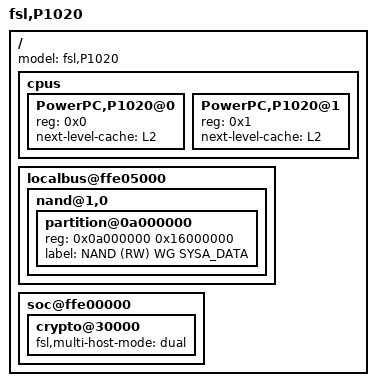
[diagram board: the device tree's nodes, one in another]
/*
 * P1020 RDB Device Tree Source
 *
 * Copyright 2010 Freescale Semiconductor Inc.
 *
 * This program is free software; you can redistribute  it and/or modify it
 * under  the terms of  the GNU General  Public License as published by the
 * Free Software Foundation;  either version 2 of the  License, or (at your
 * option) any later version.
 */


/dts-v1/;
/include/ "wg_portcastle.dtsi"
/ {
	model = "fsl,P1020";

	cpus {
		#address-cells = <1>;
		#size-cells = <0>;

		PowerPC,P1020@0 {
			device_type = "cpu";
			reg = <0x0>;
			next-level-cache = <&L2>;
		};

		PowerPC,P1020@1 {
			device_type = "cpu";
			reg = <0x1>;
			next-level-cache = <&L2>;
		};
	};

	localbus@ffe05000 {
		nand@1,0 {
			partition@0a000000 {
				/* 352MB for sysa data */
				reg = <0x0a000000 0x16000000>;
				label = "NAND (RW) WG SYSA_DATA";
			};
		};
	};

	soc@ffe00000 {
		crypto@30000 {
			fsl,multi-host-mode = "dual";
		};

	};
};
